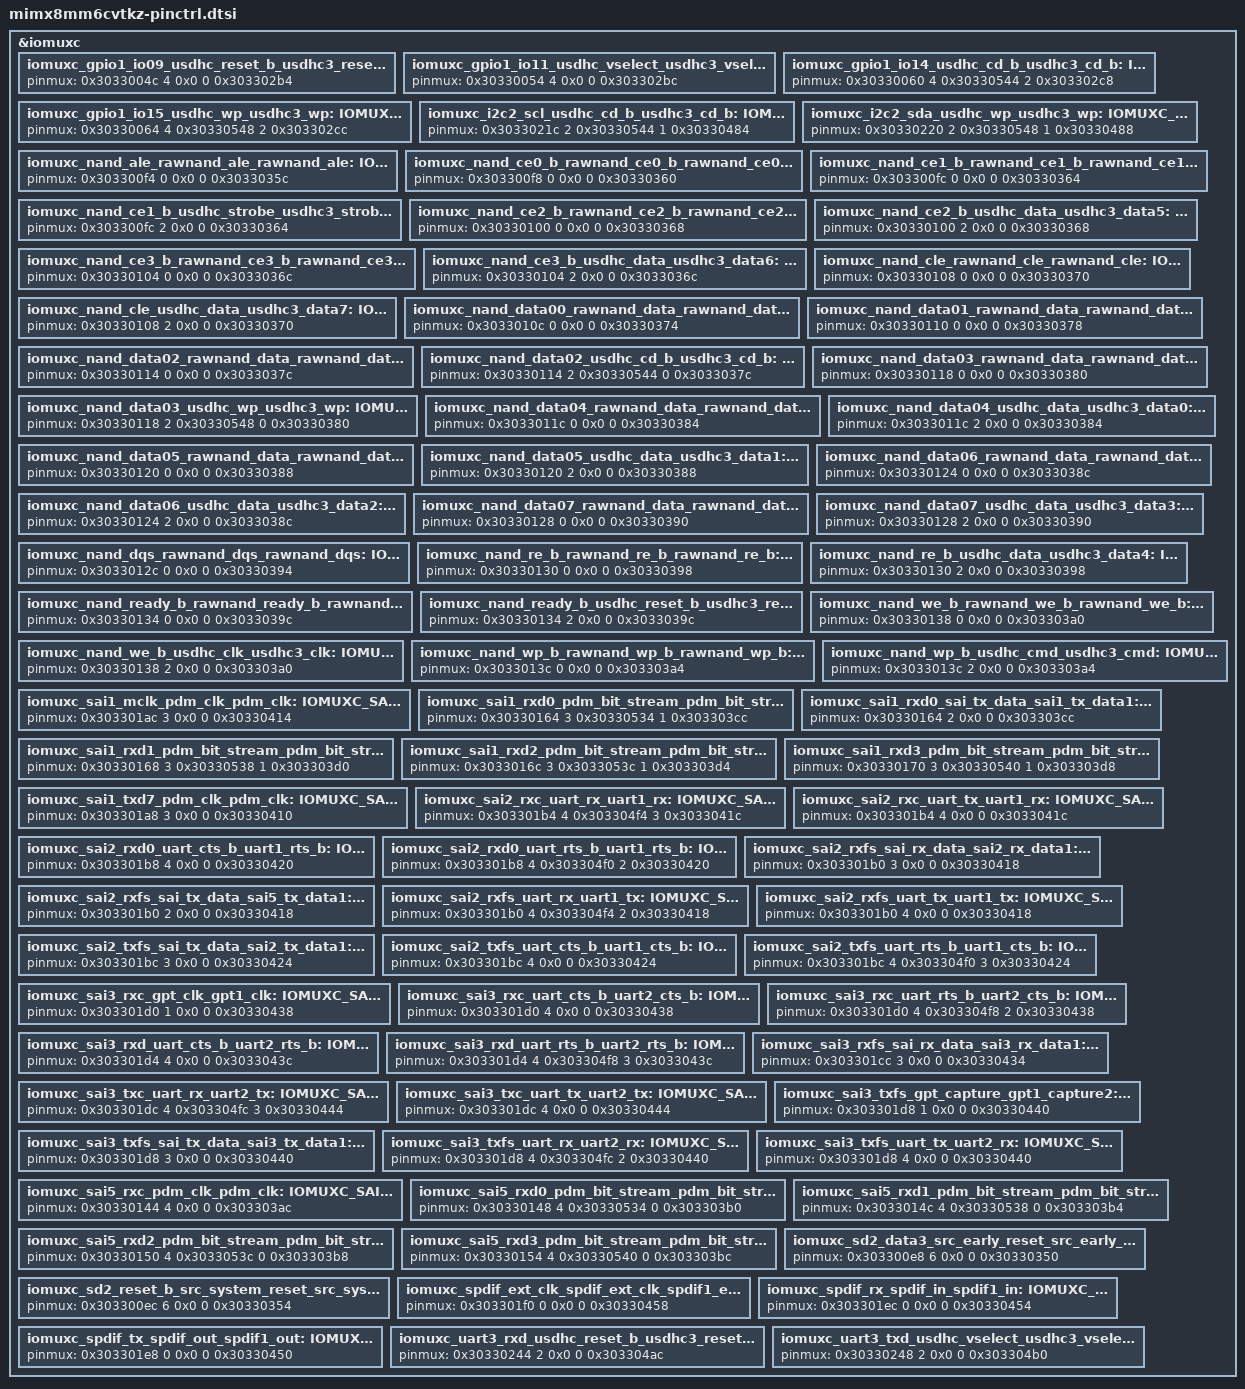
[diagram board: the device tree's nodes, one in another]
/*
 * Copyright 2024, NXP
 * SPDX-License-Identifier: Apache-2.0
 *
 * Note: File generated by gen_soc_headers.py
 * from configuration data for MIMX8MM6CVTKZ
 */

/*
 * Delta-deduplicated by dedup_pinctrl.py:
 * based on mimx8md7cvahz-pinctrl.dtsi with this part's differences applied
 * below (28 removed, 0 changed,
 * 81 added). Regenerate with dedup_pinctrl.py;
 * do not edit by hand.
 * target-hash: 2756143bb0fd5b26
 */

#include "mimx8md7cvahz-pinctrl.dtsi"

/delete-node/ &iomuxc_i2c4_sda_pcie_clkreq_b_pcie2_clkreq_b;
/delete-node/ &iomuxc_nand_ale_nand_ale_nand_ale;
/delete-node/ &iomuxc_nand_ce0_b_nand_ce0_b_nand_ce0_b;
/delete-node/ &iomuxc_nand_ce1_b_nand_ce1_b_nand_ce1_b;
/delete-node/ &iomuxc_nand_ce2_b_nand_ce2_b_nand_ce2_b;
/delete-node/ &iomuxc_nand_ce3_b_nand_ce3_b_nand_ce3_b;
/delete-node/ &iomuxc_nand_cle_nand_cle_nand_cle;
/delete-node/ &iomuxc_nand_data00_nand_data_nand_data00;
/delete-node/ &iomuxc_nand_data01_nand_data_nand_data01;
/delete-node/ &iomuxc_nand_data02_nand_data_nand_data02;
/delete-node/ &iomuxc_nand_data03_nand_data_nand_data03;
/delete-node/ &iomuxc_nand_data04_nand_data_nand_data04;
/delete-node/ &iomuxc_nand_data05_nand_data_nand_data05;
/delete-node/ &iomuxc_nand_data06_nand_data_nand_data06;
/delete-node/ &iomuxc_nand_data07_nand_data_nand_data07;
/delete-node/ &iomuxc_nand_dqs_nand_dqs_nand_dqs;
/delete-node/ &iomuxc_nand_re_b_nand_re_b_nand_re_b;
/delete-node/ &iomuxc_nand_ready_b_nand_ready_b_nand_ready_b;
/delete-node/ &iomuxc_nand_we_b_nand_we_b_nand_we_b;
/delete-node/ &iomuxc_nand_wp_b_nand_wp_b_nand_wp_b;
/delete-node/ &iomuxc_rtc_snvs_rtc_snvs_rtc;
/delete-node/ &iomuxc_sai3_rxc_gpt_capture_gpt1_capture2;
/delete-node/ &iomuxc_sai3_txfs_gpt_clk_gpt1_clk;
/delete-node/ &iomuxc_sai5_mclk_sai_mclk_sai4_mclk;
/delete-node/ &iomuxc_spdif_ext_clk_spdif_ext_clk_spdif_ext_clk;
/delete-node/ &iomuxc_spdif_rx_spdif_in_spdif_in;
/delete-node/ &iomuxc_spdif_tx_spdif_out_spdif_out;
/delete-node/ &iomuxc_uart4_txd_pcie_clkreq_b_pcie2_clkreq_b;

&iomuxc {
	/omit-if-no-ref/ iomuxc_gpio1_io09_usdhc_reset_b_usdhc3_reset_b: IOMUXC_GPIO1_IO09_USDHC_RESET_B_USDHC3_RESET_B {
		pinmux = <0x3033004c 4 0x0 0 0x303302b4>;
	};
	/omit-if-no-ref/ iomuxc_gpio1_io11_usdhc_vselect_usdhc3_vselect: IOMUXC_GPIO1_IO11_USDHC_VSELECT_USDHC3_VSELECT {
		pinmux = <0x30330054 4 0x0 0 0x303302bc>;
	};
	/omit-if-no-ref/ iomuxc_gpio1_io14_usdhc_cd_b_usdhc3_cd_b: IOMUXC_GPIO1_IO14_USDHC_CD_B_USDHC3_CD_B {
		pinmux = <0x30330060 4 0x30330544 2 0x303302c8>;
	};
	/omit-if-no-ref/ iomuxc_gpio1_io15_usdhc_wp_usdhc3_wp: IOMUXC_GPIO1_IO15_USDHC_WP_USDHC3_WP {
		pinmux = <0x30330064 4 0x30330548 2 0x303302cc>;
	};
	/omit-if-no-ref/ iomuxc_i2c2_scl_usdhc_cd_b_usdhc3_cd_b: IOMUXC_I2C2_SCL_USDHC_CD_B_USDHC3_CD_B {
		pinmux = <0x3033021c 2 0x30330544 1 0x30330484>;
	};
	/omit-if-no-ref/ iomuxc_i2c2_sda_usdhc_wp_usdhc3_wp: IOMUXC_I2C2_SDA_USDHC_WP_USDHC3_WP {
		pinmux = <0x30330220 2 0x30330548 1 0x30330488>;
	};
	/omit-if-no-ref/ iomuxc_nand_ale_rawnand_ale_rawnand_ale: IOMUXC_NAND_ALE_RAWNAND_ALE_RAWNAND_ALE {
		pinmux = <0x303300f4 0 0x0 0 0x3033035c>;
	};
	/omit-if-no-ref/ iomuxc_nand_ce0_b_rawnand_ce0_b_rawnand_ce0_b: IOMUXC_NAND_CE0_B_RAWNAND_CE0_B_RAWNAND_CE0_B {
		pinmux = <0x303300f8 0 0x0 0 0x30330360>;
	};
	/omit-if-no-ref/ iomuxc_nand_ce1_b_rawnand_ce1_b_rawnand_ce1_b: IOMUXC_NAND_CE1_B_RAWNAND_CE1_B_RAWNAND_CE1_B {
		pinmux = <0x303300fc 0 0x0 0 0x30330364>;
	};
	/omit-if-no-ref/ iomuxc_nand_ce1_b_usdhc_strobe_usdhc3_strobe: IOMUXC_NAND_CE1_B_USDHC_STROBE_USDHC3_STROBE {
		pinmux = <0x303300fc 2 0x0 0 0x30330364>;
	};
	/omit-if-no-ref/ iomuxc_nand_ce2_b_rawnand_ce2_b_rawnand_ce2_b: IOMUXC_NAND_CE2_B_RAWNAND_CE2_B_RAWNAND_CE2_B {
		pinmux = <0x30330100 0 0x0 0 0x30330368>;
	};
	/omit-if-no-ref/ iomuxc_nand_ce2_b_usdhc_data_usdhc3_data5: IOMUXC_NAND_CE2_B_USDHC_DATA_USDHC3_DATA5 {
		pinmux = <0x30330100 2 0x0 0 0x30330368>;
	};
	/omit-if-no-ref/ iomuxc_nand_ce3_b_rawnand_ce3_b_rawnand_ce3_b: IOMUXC_NAND_CE3_B_RAWNAND_CE3_B_RAWNAND_CE3_B {
		pinmux = <0x30330104 0 0x0 0 0x3033036c>;
	};
	/omit-if-no-ref/ iomuxc_nand_ce3_b_usdhc_data_usdhc3_data6: IOMUXC_NAND_CE3_B_USDHC_DATA_USDHC3_DATA6 {
		pinmux = <0x30330104 2 0x0 0 0x3033036c>;
	};
	/omit-if-no-ref/ iomuxc_nand_cle_rawnand_cle_rawnand_cle: IOMUXC_NAND_CLE_RAWNAND_CLE_RAWNAND_CLE {
		pinmux = <0x30330108 0 0x0 0 0x30330370>;
	};
	/omit-if-no-ref/ iomuxc_nand_cle_usdhc_data_usdhc3_data7: IOMUXC_NAND_CLE_USDHC_DATA_USDHC3_DATA7 {
		pinmux = <0x30330108 2 0x0 0 0x30330370>;
	};
	/omit-if-no-ref/ iomuxc_nand_data00_rawnand_data_rawnand_data00: IOMUXC_NAND_DATA00_RAWNAND_DATA_RAWNAND_DATA00 {
		pinmux = <0x3033010c 0 0x0 0 0x30330374>;
	};
	/omit-if-no-ref/ iomuxc_nand_data01_rawnand_data_rawnand_data01: IOMUXC_NAND_DATA01_RAWNAND_DATA_RAWNAND_DATA01 {
		pinmux = <0x30330110 0 0x0 0 0x30330378>;
	};
	/omit-if-no-ref/ iomuxc_nand_data02_rawnand_data_rawnand_data02: IOMUXC_NAND_DATA02_RAWNAND_DATA_RAWNAND_DATA02 {
		pinmux = <0x30330114 0 0x0 0 0x3033037c>;
	};
	/omit-if-no-ref/ iomuxc_nand_data02_usdhc_cd_b_usdhc3_cd_b: IOMUXC_NAND_DATA02_USDHC_CD_B_USDHC3_CD_B {
		pinmux = <0x30330114 2 0x30330544 0 0x3033037c>;
	};
	/omit-if-no-ref/ iomuxc_nand_data03_rawnand_data_rawnand_data03: IOMUXC_NAND_DATA03_RAWNAND_DATA_RAWNAND_DATA03 {
		pinmux = <0x30330118 0 0x0 0 0x30330380>;
	};
	/omit-if-no-ref/ iomuxc_nand_data03_usdhc_wp_usdhc3_wp: IOMUXC_NAND_DATA03_USDHC_WP_USDHC3_WP {
		pinmux = <0x30330118 2 0x30330548 0 0x30330380>;
	};
	/omit-if-no-ref/ iomuxc_nand_data04_rawnand_data_rawnand_data04: IOMUXC_NAND_DATA04_RAWNAND_DATA_RAWNAND_DATA04 {
		pinmux = <0x3033011c 0 0x0 0 0x30330384>;
	};
	/omit-if-no-ref/ iomuxc_nand_data04_usdhc_data_usdhc3_data0: IOMUXC_NAND_DATA04_USDHC_DATA_USDHC3_DATA0 {
		pinmux = <0x3033011c 2 0x0 0 0x30330384>;
	};
	/omit-if-no-ref/ iomuxc_nand_data05_rawnand_data_rawnand_data05: IOMUXC_NAND_DATA05_RAWNAND_DATA_RAWNAND_DATA05 {
		pinmux = <0x30330120 0 0x0 0 0x30330388>;
	};
	/omit-if-no-ref/ iomuxc_nand_data05_usdhc_data_usdhc3_data1: IOMUXC_NAND_DATA05_USDHC_DATA_USDHC3_DATA1 {
		pinmux = <0x30330120 2 0x0 0 0x30330388>;
	};
	/omit-if-no-ref/ iomuxc_nand_data06_rawnand_data_rawnand_data06: IOMUXC_NAND_DATA06_RAWNAND_DATA_RAWNAND_DATA06 {
		pinmux = <0x30330124 0 0x0 0 0x3033038c>;
	};
	/omit-if-no-ref/ iomuxc_nand_data06_usdhc_data_usdhc3_data2: IOMUXC_NAND_DATA06_USDHC_DATA_USDHC3_DATA2 {
		pinmux = <0x30330124 2 0x0 0 0x3033038c>;
	};
	/omit-if-no-ref/ iomuxc_nand_data07_rawnand_data_rawnand_data07: IOMUXC_NAND_DATA07_RAWNAND_DATA_RAWNAND_DATA07 {
		pinmux = <0x30330128 0 0x0 0 0x30330390>;
	};
	/omit-if-no-ref/ iomuxc_nand_data07_usdhc_data_usdhc3_data3: IOMUXC_NAND_DATA07_USDHC_DATA_USDHC3_DATA3 {
		pinmux = <0x30330128 2 0x0 0 0x30330390>;
	};
	/omit-if-no-ref/ iomuxc_nand_dqs_rawnand_dqs_rawnand_dqs: IOMUXC_NAND_DQS_RAWNAND_DQS_RAWNAND_DQS {
		pinmux = <0x3033012c 0 0x0 0 0x30330394>;
	};
	/omit-if-no-ref/ iomuxc_nand_re_b_rawnand_re_b_rawnand_re_b: IOMUXC_NAND_RE_B_RAWNAND_RE_B_RAWNAND_RE_B {
		pinmux = <0x30330130 0 0x0 0 0x30330398>;
	};
	/omit-if-no-ref/ iomuxc_nand_re_b_usdhc_data_usdhc3_data4: IOMUXC_NAND_RE_B_USDHC_DATA_USDHC3_DATA4 {
		pinmux = <0x30330130 2 0x0 0 0x30330398>;
	};
	/omit-if-no-ref/ iomuxc_nand_ready_b_rawnand_ready_b_rawnand_ready_b: IOMUXC_NAND_READY_B_RAWNAND_READY_B_RAWNAND_READY_B {
		pinmux = <0x30330134 0 0x0 0 0x3033039c>;
	};
	/omit-if-no-ref/ iomuxc_nand_ready_b_usdhc_reset_b_usdhc3_reset_b: IOMUXC_NAND_READY_B_USDHC_RESET_B_USDHC3_RESET_B {
		pinmux = <0x30330134 2 0x0 0 0x3033039c>;
	};
	/omit-if-no-ref/ iomuxc_nand_we_b_rawnand_we_b_rawnand_we_b: IOMUXC_NAND_WE_B_RAWNAND_WE_B_RAWNAND_WE_B {
		pinmux = <0x30330138 0 0x0 0 0x303303a0>;
	};
	/omit-if-no-ref/ iomuxc_nand_we_b_usdhc_clk_usdhc3_clk: IOMUXC_NAND_WE_B_USDHC_CLK_USDHC3_CLK {
		pinmux = <0x30330138 2 0x0 0 0x303303a0>;
	};
	/omit-if-no-ref/ iomuxc_nand_wp_b_rawnand_wp_b_rawnand_wp_b: IOMUXC_NAND_WP_B_RAWNAND_WP_B_RAWNAND_WP_B {
		pinmux = <0x3033013c 0 0x0 0 0x303303a4>;
	};
	/omit-if-no-ref/ iomuxc_nand_wp_b_usdhc_cmd_usdhc3_cmd: IOMUXC_NAND_WP_B_USDHC_CMD_USDHC3_CMD {
		pinmux = <0x3033013c 2 0x0 0 0x303303a4>;
	};
	/omit-if-no-ref/ iomuxc_sai1_mclk_pdm_clk_pdm_clk: IOMUXC_SAI1_MCLK_PDM_CLK_PDM_CLK {
		pinmux = <0x303301ac 3 0x0 0 0x30330414>;
	};
	/omit-if-no-ref/ iomuxc_sai1_rxd0_pdm_bit_stream_pdm_bit_stream0: IOMUXC_SAI1_RXD0_PDM_BIT_STREAM_PDM_BIT_STREAM0 {
		pinmux = <0x30330164 3 0x30330534 1 0x303303cc>;
	};
	/omit-if-no-ref/ iomuxc_sai1_rxd0_sai_tx_data_sai1_tx_data1: IOMUXC_SAI1_RXD0_SAI_TX_DATA_SAI1_TX_DATA1 {
		pinmux = <0x30330164 2 0x0 0 0x303303cc>;
	};
	/omit-if-no-ref/ iomuxc_sai1_rxd1_pdm_bit_stream_pdm_bit_stream1: IOMUXC_SAI1_RXD1_PDM_BIT_STREAM_PDM_BIT_STREAM1 {
		pinmux = <0x30330168 3 0x30330538 1 0x303303d0>;
	};
	/omit-if-no-ref/ iomuxc_sai1_rxd2_pdm_bit_stream_pdm_bit_stream2: IOMUXC_SAI1_RXD2_PDM_BIT_STREAM_PDM_BIT_STREAM2 {
		pinmux = <0x3033016c 3 0x3033053c 1 0x303303d4>;
	};
	/omit-if-no-ref/ iomuxc_sai1_rxd3_pdm_bit_stream_pdm_bit_stream3: IOMUXC_SAI1_RXD3_PDM_BIT_STREAM_PDM_BIT_STREAM3 {
		pinmux = <0x30330170 3 0x30330540 1 0x303303d8>;
	};
	/omit-if-no-ref/ iomuxc_sai1_txd7_pdm_clk_pdm_clk: IOMUXC_SAI1_TXD7_PDM_CLK_PDM_CLK {
		pinmux = <0x303301a8 3 0x0 0 0x30330410>;
	};
	/omit-if-no-ref/ iomuxc_sai2_rxc_uart_rx_uart1_rx: IOMUXC_SAI2_RXC_UART_RX_UART1_RX {
		pinmux = <0x303301b4 4 0x303304f4 3 0x3033041c>;
	};
	/omit-if-no-ref/ iomuxc_sai2_rxc_uart_tx_uart1_rx: IOMUXC_SAI2_RXC_UART_TX_UART1_RX {
		pinmux = <0x303301b4 4 0x0 0 0x3033041c>;
	};
	/omit-if-no-ref/ iomuxc_sai2_rxd0_uart_cts_b_uart1_rts_b: IOMUXC_SAI2_RXD0_UART_CTS_B_UART1_RTS_B {
		pinmux = <0x303301b8 4 0x0 0 0x30330420>;
	};
	/omit-if-no-ref/ iomuxc_sai2_rxd0_uart_rts_b_uart1_rts_b: IOMUXC_SAI2_RXD0_UART_RTS_B_UART1_RTS_B {
		pinmux = <0x303301b8 4 0x303304f0 2 0x30330420>;
	};
	/omit-if-no-ref/ iomuxc_sai2_rxfs_sai_rx_data_sai2_rx_data1: IOMUXC_SAI2_RXFS_SAI_RX_DATA_SAI2_RX_DATA1 {
		pinmux = <0x303301b0 3 0x0 0 0x30330418>;
	};
	/omit-if-no-ref/ iomuxc_sai2_rxfs_sai_tx_data_sai5_tx_data1: IOMUXC_SAI2_RXFS_SAI_TX_DATA_SAI5_TX_DATA1 {
		pinmux = <0x303301b0 2 0x0 0 0x30330418>;
	};
	/omit-if-no-ref/ iomuxc_sai2_rxfs_uart_rx_uart1_tx: IOMUXC_SAI2_RXFS_UART_RX_UART1_TX {
		pinmux = <0x303301b0 4 0x303304f4 2 0x30330418>;
	};
	/omit-if-no-ref/ iomuxc_sai2_rxfs_uart_tx_uart1_tx: IOMUXC_SAI2_RXFS_UART_TX_UART1_TX {
		pinmux = <0x303301b0 4 0x0 0 0x30330418>;
	};
	/omit-if-no-ref/ iomuxc_sai2_txfs_sai_tx_data_sai2_tx_data1: IOMUXC_SAI2_TXFS_SAI_TX_DATA_SAI2_TX_DATA1 {
		pinmux = <0x303301bc 3 0x0 0 0x30330424>;
	};
	/omit-if-no-ref/ iomuxc_sai2_txfs_uart_cts_b_uart1_cts_b: IOMUXC_SAI2_TXFS_UART_CTS_B_UART1_CTS_B {
		pinmux = <0x303301bc 4 0x0 0 0x30330424>;
	};
	/omit-if-no-ref/ iomuxc_sai2_txfs_uart_rts_b_uart1_cts_b: IOMUXC_SAI2_TXFS_UART_RTS_B_UART1_CTS_B {
		pinmux = <0x303301bc 4 0x303304f0 3 0x30330424>;
	};
	/omit-if-no-ref/ iomuxc_sai3_rxc_gpt_clk_gpt1_clk: IOMUXC_SAI3_RXC_GPT_CLK_GPT1_CLK {
		pinmux = <0x303301d0 1 0x0 0 0x30330438>;
	};
	/omit-if-no-ref/ iomuxc_sai3_rxc_uart_cts_b_uart2_cts_b: IOMUXC_SAI3_RXC_UART_CTS_B_UART2_CTS_B {
		pinmux = <0x303301d0 4 0x0 0 0x30330438>;
	};
	/omit-if-no-ref/ iomuxc_sai3_rxc_uart_rts_b_uart2_cts_b: IOMUXC_SAI3_RXC_UART_RTS_B_UART2_CTS_B {
		pinmux = <0x303301d0 4 0x303304f8 2 0x30330438>;
	};
	/omit-if-no-ref/ iomuxc_sai3_rxd_uart_cts_b_uart2_rts_b: IOMUXC_SAI3_RXD_UART_CTS_B_UART2_RTS_B {
		pinmux = <0x303301d4 4 0x0 0 0x3033043c>;
	};
	/omit-if-no-ref/ iomuxc_sai3_rxd_uart_rts_b_uart2_rts_b: IOMUXC_SAI3_RXD_UART_RTS_B_UART2_RTS_B {
		pinmux = <0x303301d4 4 0x303304f8 3 0x3033043c>;
	};
	/omit-if-no-ref/ iomuxc_sai3_rxfs_sai_rx_data_sai3_rx_data1: IOMUXC_SAI3_RXFS_SAI_RX_DATA_SAI3_RX_DATA1 {
		pinmux = <0x303301cc 3 0x0 0 0x30330434>;
	};
	/omit-if-no-ref/ iomuxc_sai3_txc_uart_rx_uart2_tx: IOMUXC_SAI3_TXC_UART_RX_UART2_TX {
		pinmux = <0x303301dc 4 0x303304fc 3 0x30330444>;
	};
	/omit-if-no-ref/ iomuxc_sai3_txc_uart_tx_uart2_tx: IOMUXC_SAI3_TXC_UART_TX_UART2_TX {
		pinmux = <0x303301dc 4 0x0 0 0x30330444>;
	};
	/omit-if-no-ref/ iomuxc_sai3_txfs_gpt_capture_gpt1_capture2: IOMUXC_SAI3_TXFS_GPT_CAPTURE_GPT1_CAPTURE2 {
		pinmux = <0x303301d8 1 0x0 0 0x30330440>;
	};
	/omit-if-no-ref/ iomuxc_sai3_txfs_sai_tx_data_sai3_tx_data1: IOMUXC_SAI3_TXFS_SAI_TX_DATA_SAI3_TX_DATA1 {
		pinmux = <0x303301d8 3 0x0 0 0x30330440>;
	};
	/omit-if-no-ref/ iomuxc_sai3_txfs_uart_rx_uart2_rx: IOMUXC_SAI3_TXFS_UART_RX_UART2_RX {
		pinmux = <0x303301d8 4 0x303304fc 2 0x30330440>;
	};
	/omit-if-no-ref/ iomuxc_sai3_txfs_uart_tx_uart2_rx: IOMUXC_SAI3_TXFS_UART_TX_UART2_RX {
		pinmux = <0x303301d8 4 0x0 0 0x30330440>;
	};
	/omit-if-no-ref/ iomuxc_sai5_rxc_pdm_clk_pdm_clk: IOMUXC_SAI5_RXC_PDM_CLK_PDM_CLK {
		pinmux = <0x30330144 4 0x0 0 0x303303ac>;
	};
	/omit-if-no-ref/ iomuxc_sai5_rxd0_pdm_bit_stream_pdm_bit_stream0: IOMUXC_SAI5_RXD0_PDM_BIT_STREAM_PDM_BIT_STREAM0 {
		pinmux = <0x30330148 4 0x30330534 0 0x303303b0>;
	};
	/omit-if-no-ref/ iomuxc_sai5_rxd1_pdm_bit_stream_pdm_bit_stream1: IOMUXC_SAI5_RXD1_PDM_BIT_STREAM_PDM_BIT_STREAM1 {
		pinmux = <0x3033014c 4 0x30330538 0 0x303303b4>;
	};
	/omit-if-no-ref/ iomuxc_sai5_rxd2_pdm_bit_stream_pdm_bit_stream2: IOMUXC_SAI5_RXD2_PDM_BIT_STREAM_PDM_BIT_STREAM2 {
		pinmux = <0x30330150 4 0x3033053c 0 0x303303b8>;
	};
	/omit-if-no-ref/ iomuxc_sai5_rxd3_pdm_bit_stream_pdm_bit_stream3: IOMUXC_SAI5_RXD3_PDM_BIT_STREAM_PDM_BIT_STREAM3 {
		pinmux = <0x30330154 4 0x30330540 0 0x303303bc>;
	};
	/omit-if-no-ref/ iomuxc_sd2_data3_src_early_reset_src_early_reset: IOMUXC_SD2_DATA3_SRC_EARLY_RESET_SRC_EARLY_RESET {
		pinmux = <0x303300e8 6 0x0 0 0x30330350>;
	};
	/omit-if-no-ref/ iomuxc_sd2_reset_b_src_system_reset_src_system_reset: IOMUXC_SD2_RESET_B_SRC_SYSTEM_RESET_SRC_SYSTEM_RESET {
		pinmux = <0x303300ec 6 0x0 0 0x30330354>;
	};
	/omit-if-no-ref/ iomuxc_spdif_ext_clk_spdif_ext_clk_spdif1_ext_clk: IOMUXC_SPDIF_EXT_CLK_SPDIF_EXT_CLK_SPDIF1_EXT_CLK {
		pinmux = <0x303301f0 0 0x0 0 0x30330458>;
	};
	/omit-if-no-ref/ iomuxc_spdif_rx_spdif_in_spdif1_in: IOMUXC_SPDIF_RX_SPDIF_IN_SPDIF1_IN {
		pinmux = <0x303301ec 0 0x0 0 0x30330454>;
	};
	/omit-if-no-ref/ iomuxc_spdif_tx_spdif_out_spdif1_out: IOMUXC_SPDIF_TX_SPDIF_OUT_SPDIF1_OUT {
		pinmux = <0x303301e8 0 0x0 0 0x30330450>;
	};
	/omit-if-no-ref/ iomuxc_uart3_rxd_usdhc_reset_b_usdhc3_reset_b: IOMUXC_UART3_RXD_USDHC_RESET_B_USDHC3_RESET_B {
		pinmux = <0x30330244 2 0x0 0 0x303304ac>;
	};
	/omit-if-no-ref/ iomuxc_uart3_txd_usdhc_vselect_usdhc3_vselect: IOMUXC_UART3_TXD_USDHC_VSELECT_USDHC3_VSELECT {
		pinmux = <0x30330248 2 0x0 0 0x303304b0>;
	};
};
